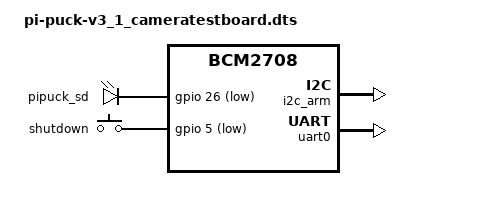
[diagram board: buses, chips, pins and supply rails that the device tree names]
/dts-v1/;
/plugin/;

/ {
	compatible = "brcm,bcm2708";

	/* I2C devices */
	fragment@0 {
		target = <&i2c_arm>;
		__overlay__ {
			#address-cells = <1>;
			#size-cells = <0>;
			status = "okay";
			/* e-puck */
			/* FT903 slave */
		};
	};

	/* SD LED (on Raspberry Pi pin) */
	fragment@1 {
		target-path = "/soc";
		__overlay__ {
			pipuck_sd_led {
				compatible = "gpio-leds";
				pipuck_sd {
					label = "pipuck_sd";
					gpios = <&gpio 26 1>;
					linux,default-trigger = "mmc0";
				};
			};
		};
	};

	/* Shutdown button key */
	fragment@2 {
		target-path = "/soc";
		__overlay__ {
			pipuck_shutdown_key {
				compatible = "gpio-keys";
				pipuck_shutdown: pipuck_shutdown {
					label = "shutdown";
					linux,code = <116>; // KEY_POWER
					gpios = <&gpio 5 1>;
					debounce-interval = <1000>;
				};
			};
		};
	};

	/* Disable Bluetooth to free up UART */
	fragment@3 {
		target = <&uart1>;
		__overlay__ {
			status = "disabled";
		};
	};
	fragment@4 {
		target = <&uart0>;
		__overlay__ {
			pinctrl-names = "default";
			pinctrl-0 = <&uart0_pins>;
			status = "okay";
		};
	};
	fragment@5 {
		target = <&uart0_pins>;
		__overlay__ {
			brcm,pins;
			brcm,function;
			brcm,pull;
		};
	};
	fragment@6 {
		target-path = "/aliases";
		__overlay__ {
			serial0 = "/soc/serial@7e201000";
			serial1 = "/soc/serial@7e215040";
		};
	};

	__overrides__ {
		shutdown_key_disable = <0>,"-2";
		shutdown_key_debounce = <&pipuck_shutdown>,"debounce-interval:0";
		uart_disable = <0>,"-3-4-5-6";
	};
};
